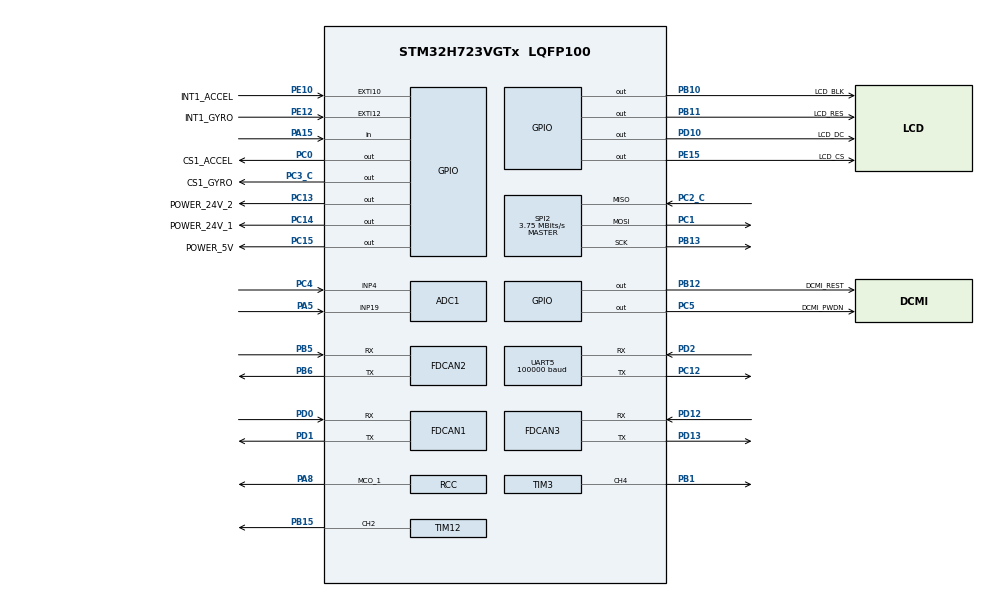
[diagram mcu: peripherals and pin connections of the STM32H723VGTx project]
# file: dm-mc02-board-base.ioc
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ADC1.Channel-0\#ChannelRegularConversion=ADC_CHANNEL_4
ADC1.Channel-1\#ChannelRegularConversion=ADC_CHANNEL_19
ADC1.ClockPrescaler=ADC_CLOCK_ASYNC_DIV64
ADC1.ContinuousConvMode=ENABLE
ADC1.ConversionDataManagement=ADC_CONVERSIONDATA_DMA_CIRCULAR
ADC1.NbrOfConversion=2
ADC1.NbrOfConversionFlag=1
ADC1.OffsetNumber-0\#ChannelRegularConversion=ADC_OFFSET_NONE
ADC1.OffsetNumber-1\#ChannelRegularConversion=ADC_OFFSET_NONE
ADC1.OffsetSignedSaturation-0\#ChannelRegularConversion=DISABLE
ADC1.OffsetSignedSaturation-1\#ChannelRegularConversion=DISABLE
ADC1.Rank-0\#ChannelRegularConversion=1
ADC1.Rank-1\#ChannelRegularConversion=2
ADC1.SamplingTime-0\#ChannelRegularConversion=ADC_SAMPLETIME_32CYCLES_5
ADC1.SamplingTime-1\#ChannelRegularConversion=ADC_SAMPLETIME_32CYCLES_5
ADC1.master=1
CORTEX_M7.BaseAddress-Cortex_Memory_Protection_Unit_Region0_Settings=0x24000000
CORTEX_M7.CPU_DCache=Disabled
CORTEX_M7.CPU_ICache=Disabled
CORTEX_M7.Enable-Cortex_Memory_Protection_Unit_Region0_Settings=MPU_REGION_ENABLE
CORTEX_M7.IsBufferable-Cortex_Memory_Protection_Unit_Region0_Settings=MPU_ACCESS_BUFFERABLE
CORTEX_M7.IsCacheable-Cortex_Memory_Protection_Unit_Region0_Settings=MPU_ACCESS_CACHEABLE
CORTEX_M7.MPU_Control=__NULL
CORTEX_M7.Size-Cortex_Memory_Protection_Unit_Region0_Settings=MPU_REGION_SIZE_512B
CORTEX_M7.TypeExtField-Cortex_Memory_Protection_Unit_Region0_Settings=MPU_TEX_LEVEL1
Dma.ADC1.0.Direction=DMA_PERIPH_TO_MEMORY
Dma.ADC1.0.EventEnable=DISABLE
Dma.ADC1.0.FIFOMode=DMA_FIFOMODE_DISABLE
Dma.ADC1.0.Instance=DMA1_Stream0
Dma.ADC1.0.MemDataAlignment=DMA_MDATAALIGN_HALFWORD
Dma.ADC1.0.MemInc=DMA_MINC_ENABLE
Dma.ADC1.0.Mode=DMA_CIRCULAR
Dma.ADC1.0.PeriphDataAlignment=DMA_PDATAALIGN_HALFWORD
Dma.ADC1.0.PeriphInc=DMA_PINC_DISABLE
Dma.ADC1.0.Polarity=HAL_DMAMUX_REQ_GEN_RISING
Dma.ADC1.0.Priority=DMA_PRIORITY_LOW
Dma.ADC1.0.RequestNumber=1
Dma.ADC1.0.SignalID=NONE
Dma.ADC1.0.SyncEnable=DISABLE
Dma.ADC1.0.SyncPolarity=HAL_DMAMUX_SYNC_NO_EVENT
Dma.ADC1.0.SyncRequestNumber=1
Dma.ADC1.0.SyncSignalID=NONE
Dma.Request0=ADC1
Dma.Request1=UART5_RX
Dma.UART5_RX.1.Direction=DMA_PERIPH_TO_MEMORY
Dma.UART5_RX.1.EventEnable=DISABLE
Dma.UART5_RX.1.FIFOMode=DMA_FIFOMODE_DISABLE
Dma.UART5_RX.1.Instance=DMA1_Stream1
Dma.UART5_RX.1.MemDataAlignment=DMA_MDATAALIGN_BYTE
Dma.UART5_RX.1.MemInc=DMA_MINC_ENABLE
Dma.UART5_RX.1.Mode=DMA_NORMAL
Dma.UART5_RX.1.PeriphDataAlignment=DMA_PDATAALIGN_BYTE
Dma.UART5_RX.1.PeriphInc=DMA_PINC_DISABLE
Dma.UART5_RX.1.Polarity=HAL_DMAMUX_REQ_GEN_RISING
Dma.UART5_RX.1.Priority=DMA_PRIORITY_VERY_HIGH
Dma.UART5_RX.1.RequestNumber=1
Dma.UART5_RX.1.SignalID=NONE
Dma.UART5_RX.1.SyncEnable=DISABLE
Dma.UART5_RX.1.SyncPolarity=HAL_DMAMUX_SYNC_NO_EVENT
Dma.UART5_RX.1.SyncRequestNumber=1
Dma.UART5_RX.1.SyncSignalID=NONE
FDCAN1.CalculateBaudRateNominal=1000000
FDCAN1.CalculateTimeBitNominal=1000
FDCAN1.CalculateTimeQuantumNominal=200.0
FDCAN1.NominalPrescaler=24
FDCAN1.NominalTimeSeg1=2
FDCAN1.RxFifo0ElmtsNbr=32
FDCAN1.StdFiltersNbr=1
FDCAN1.TxFifoQueueElmtsNbr=32
FDCAN2.CalculateBaudRateNominal=1000000
FDCAN2.CalculateTimeBitNominal=1000
FDCAN2.CalculateTimeQuantumNominal=200.0
FDCAN2.MessageRAMOffset=0x406
FDCAN2.NominalPrescaler=24
FDCAN2.RxFifo0ElmtsNbr=32
FDCAN2.StdFiltersNbr=1
FDCAN2.TxFifoQueueElmtsNbr=32
FDCAN3.CalculateBaudRateNominal=1000000
FDCAN3.CalculateTimeBitNominal=1000
FDCAN3.CalculateTimeQuantumNominal=200.0
FDCAN3.MessageRAMOffset=0x812
FDCAN3.NominalPrescaler=24
FDCAN3.RxFifo0ElmtsNbr=32
FDCAN3.StdFiltersNbr=1
FDCAN3.TxFifoQueueElmtsNbr=32
FREERTOS.INCLUDE_eTaskGetState=1
FREERTOS.INCLUDE_uxTaskGetStackHighWaterMark=1
FREERTOS.INCLUDE_vTaskDelayUntil=1
FREERTOS.INCLUDE_xQueueGetMutexHolder=1
FREERTOS.INCLUDE_xTaskGetCurrentTaskHandle=1
FREERTOS.INCLUDE_xTimerPendFunctionCall=1
FREERTOS.Tasks01=defaultTask,0,128,StartDefaultTask,Default,NULL,Dynamic,NULL,NULL
FREERTOS.configENABLE_FPU=1
FREERTOS.configGENERATE_RUN_TIME_STATS=1
FREERTOS.configRECORD_STACK_HIGH_ADDRESS=1
FREERTOS.configUSE_COUNTING_SEMAPHORES=1
FREERTOS.configUSE_RECURSIVE_MUTEXES=1
FREERTOS.configUSE_TIMERS=1
FREERTOS.configUSE_TRACE_FACILITY=1
Mcu.Family=STM32H7
Mcu.Name=STM32H723VGTx
Mcu.Package=LQFP100
NVIC.DMA1_Stream0_IRQn=true\:5\:0\:false\:false\:true\:false\:false\:true\:true
NVIC.DMA1_Stream1_IRQn=true\:5\:0\:false\:false\:true\:true\:false\:true\:true
NVIC.FDCAN1_IT0_IRQn=true\:5\:0\:false\:false\:true\:true\:true\:true\:true
NVIC.FDCAN1_IT1_IRQn=true\:5\:0\:false\:false\:true\:true\:true\:true\:true
NVIC.FDCAN2_IT0_IRQn=true\:5\:0\:false\:false\:true\:true\:true\:true\:true
NVIC.FDCAN2_IT1_IRQn=true\:5\:0\:false\:false\:true\:true\:true\:true\:true
NVIC.FDCAN3_IT0_IRQn=true\:5\:0\:false\:false\:true\:true\:true\:true\:true
NVIC.FDCAN3_IT1_IRQn=true\:5\:0\:false\:false\:true\:true\:true\:true\:true
NVIC.PriorityGroup=NVIC_PRIORITYGROUP_4
NVIC.TIM23_IRQn=true\:15\:0\:false\:false\:true\:false\:false\:true\:true
NVIC.TimeBase=TIM23_IRQn
NVIC.TimeBaseIP=TIM23
NVIC.UART5_IRQn=true\:5\:0\:false\:false\:true\:true\:true\:true\:true
PA0.Signal=S_TIM2_CH1_ETR
PA1.Signal=OCTOSPIM_P1_IO3
PA10.Signal=USART1_RX
PA13(JTMS/SWDIO).Mode=Serial_Wire
PA13(JTMS/SWDIO).Signal=DEBUG_JTMS-SWDIO
PA14(JTCK/SWCLK).Mode=Serial_Wire
PA14(JTCK/SWCLK).Signal=DEBUG_JTCK-SWCLK
PA15(JTDI).Signal=GPIO_Input
PA2.Signal=S_TIM2_CH3
PA3.Signal=OCTOSPIM_P1_IO2
PA5.Signal=ADCx_INP19
PA8.Mode=Clock-out-1
PA8.Signal=RCC_MCO_1
PA9.Signal=USART1_TX
PB0.Signal=OCTOSPIM_P1_IO1
PB1.Signal=S_TIM3_CH4
PB10.GPIO_Label=LCD_BLK
PB10.Signal=GPIO_Output
PB11.GPIO_Label=LCD_RES
PB11.Signal=GPIO_Output
PB12.GPIO_Label=DCMI_REST
PB12.GPIO_PuPd=GPIO_PULLUP
PB12.GPIO_Speed=GPIO_SPEED_FREQ_VERY_HIGH
PB12.PinState=GPIO_PIN_SET
PB12.Signal=GPIO_Output
PB13.GPIO_Speed=GPIO_SPEED_FREQ_VERY_HIGH
PB13.Mode=Full_Duplex_Master
PB13.Signal=SPI2_SCK
PB15.Signal=S_TIM12_CH2
PB2.Signal=OCTOSPIM_P1_CLK
PB5.Mode=FDCAN_Activate
PB5.Signal=FDCAN2_RX
PB6.Mode=FDCAN_Activate
PB6.Signal=FDCAN2_TX
PC0.GPIO_Label=CS1_ACCEL
PC0.GPIO_Speed=GPIO_SPEED_FREQ_VERY_HIGH
PC0.PinState=GPIO_PIN_SET
PC0.Signal=GPIO_Output
PC1.GPIO_Speed=GPIO_SPEED_FREQ_VERY_HIGH
PC1.Mode=Full_Duplex_Master
PC1.Signal=SPI2_MOSI
PC12.Mode=Asynchronous
PC12.Signal=UART5_TX
PC13.GPIO_Label=POWER_24V_2
PC13.PinState=GPIO_PIN_SET
PC13.Signal=GPIO_Output
PC14-OSC32_IN.GPIO_Label=POWER_24V_1
PC14-OSC32_IN.PinState=GPIO_PIN_SET
PC14-OSC32_IN.Signal=GPIO_Output
PC15-OSC32_OUT.GPIO_Label=POWER_5V
PC15-OSC32_OUT.PinState=GPIO_PIN_SET
PC15-OSC32_OUT.Signal=GPIO_Output
PC2_C.GPIO_Speed=GPIO_SPEED_FREQ_VERY_HIGH
PC2_C.Mode=Full_Duplex_Master
PC2_C.Signal=SPI2_MISO
PC3_C.GPIO_Label=CS1_GYRO
PC3_C.GPIO_Speed=GPIO_SPEED_FREQ_VERY_HIGH
PC3_C.PinState=GPIO_PIN_SET
PC3_C.Signal=GPIO_Output
PC4.Signal=ADCx_INP4
PC5.GPIO_Label=DCMI_PWDN
PC5.GPIO_PuPd=GPIO_NOPULL
PC5.GPIO_Speed=GPIO_SPEED_FREQ_VERY_HIGH
PC5.PinState=GPIO_PIN_SET
PC5.Signal=GPIO_Output
PD0.Mode=FDCAN_Activate
PD0.Signal=FDCAN1_RX
PD1.Mode=FDCAN_Activate
PD1.Signal=FDCAN1_TX
PD10.GPIO_Label=LCD_DC
PD10.Signal=GPIO_Output
PD11.Signal=OCTOSPIM_P1_IO0
PD12.Mode=FDCAN_Activate
PD12.Signal=FDCAN3_RX
PD13.Mode=FDCAN_Activate
PD13.Signal=FDCAN3_TX
PD2.GPIO_Speed=GPIO_SPEED_FREQ_VERY_HIGH
PD2.Mode=Asynchronous
PD2.Signal=UART5_RX
PD4.Signal=USART2_DE
PD5.Signal=USART2_TX
PD6.Signal=USART2_RX
PD7.GPIO_Speed=GPIO_SPEED_FREQ_VERY_HIGH
PD7.Signal=SPI1_MOSI
PE10.GPIO_Label=INT1_ACCEL
PE10.Signal=GPXTI10
PE11.Signal=OCTOSPIM_P1_NCS
PE12.GPIO_Label=INT1_GYRO
PE12.Signal=GPXTI12
PE15.GPIO_Label=LCD_CS
PE15.Signal=GPIO_Output
PE9.Signal=S_TIM1_CH1
PH0-OSC_IN.Mode=HSE-External-Oscillator
PH0-OSC_IN.Signal=RCC_OSC_IN
PH1-OSC_OUT.Mode=HSE-External-Oscillator
PH1-OSC_OUT.Signal=RCC_OSC_OUT
ProjectManager.HeapSize=0x200
ProjectManager.StackSize=0x800
ProjectManager.TargetToolchain=Makefile
RCC.ADCFreq_Value=96000000
RCC.APB1Freq_Value=120000000
RCC.APB2Freq_Value=120000000
RCC.APB3Freq_Value=120000000
RCC.APB4Freq_Value=120000000
RCC.CortexFreq_Value=480000000
RCC.D1PPRE=RCC_APB3_DIV2
RCC.D2PPRE1=RCC_APB1_DIV2
RCC.D2PPRE2=RCC_APB2_DIV2
RCC.D3PPRE=RCC_APB4_DIV2
RCC.DIVM1=2
RCC.DIVM2=2
RCC.DIVN1=40
RCC.DIVN2=16
RCC.DIVP1=1
RCC.DIVQ1=4
RCC.EnbaleCSS=false
RCC.HCLKFreq_Value=240000000
RCC.HPRE=RCC_HCLK_DIV2
RCC.HSE_VALUE=24000000
RCC.PLL2FRACN=0
RCC.PLL2_VCI_Range-AdvancedSettings=RCC_PLL2VCIRANGE_0
RCC.PLL2_VCO_SEL-AdvancedSettings=RCC_PLL2VCOWIDE
RCC.PLL3FRACN=0
RCC.PLL3_VCO_SEL-AdvancedSettings=RCC_PLL3VCOMEDIUM
RCC.PLLFRACN=0
RCC.PLLSourceVirtual=RCC_PLLSOURCE_HSE
RCC.SPI6CLockSelection=RCC_SPI6CLKSOURCE_HSE
RCC.SYSCLKFreq_VALUE=480000000
RCC.SYSCLKSource=RCC_SYSCLKSOURCE_PLLCLK
RCC.USBCLockSelection=RCC_USBCLKSOURCE_HSI48
RCC.USBFreq_Value=48000000
SH.ADCx_INP19.0=ADC1_INP19,IN19-Single-Ended
SH.ADCx_INP4.0=ADC1_INP4,IN4-Single-Ended
SH.S_TIM12_CH2.0=TIM12_CH2,PWM Generation2 CH2
SH.S_TIM1_CH1.0=TIM1_CH1
SH.S_TIM2_CH1_ETR.0=TIM2_CH1
SH.S_TIM2_CH3.0=TIM2_CH3
SH.S_TIM3_CH4.0=TIM3_CH4,PWM Generation4 CH4
SPI2.BaudRatePrescaler=SPI_BAUDRATEPRESCALER_32
SPI2.CLKPhase=SPI_PHASE_2EDGE
SPI2.CLKPolarity=SPI_POLARITY_HIGH
SPI2.CalculateBaudRate=3.75 MBits/s
SPI2.DataSize=SPI_DATASIZE_8BIT
SPI2.Direction=SPI_DIRECTION_2LINES
SPI2.Mode=SPI_MODE_MASTER
SPI2.VirtualType=VM_MASTER
TIM12.Channel-PWM\ Generation2\ CH2=TIM_CHANNEL_2
TIM12.Period=65535
TIM12.Prescaler=24-1
TIM3.AutoReloadPreload=TIM_AUTORELOAD_PRELOAD_ENABLE
TIM3.Channel-PWM\ Generation4\ CH4=TIM_CHANNEL_4
TIM3.Period=10000-1
TIM3.Prescaler=24-1
TIM6.Prescaler=12000-1
UART5.BaudRate=100000
UART5.Parity=PARITY_EVEN
UART5.StopBits=UART_STOPBITS_2
UART5.WordLength=WORDLENGTH_9B
VP_FREERTOS_VS_CMSIS_V1.Mode=CMSIS_V1
VP_MEMORYMAP_VS_MEMORYMAP.Mode=CurAppReg
VP_SYS_VS_tim23.Mode=TIM23
VP_TIM6_VS_ClockSourceINT.Mode=Enable_Timer
board=custom

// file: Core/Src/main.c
/* USER CODE BEGIN Header */
/**
  ******************************************************************************
  * @file           : main.c
  * @brief          : Main program body
  ******************************************************************************
  * @attention
  *
  * Copyright (c) 2024 STMicroelectronics.
  * All rights reserved.
  *
  * This software is licensed under terms that can be found in the LICENSE file
  * in the root directory of this software component.
  * If no LICENSE file comes with this software, it is provided AS-IS.
  *
  ******************************************************************************
  */
/* USER CODE END Header */
#include "main.h"
#include "cmsis_os.h"
#include "adc.h"
#include "dma.h"
#include "fdcan.h"
#include "memorymap.h"
#include "spi.h"
#include "tim.h"
#include "usart.h"
#include "gpio.h"

/* USER CODE BEGIN Includes */
#include "robot.h"
/* USER CODE END Includes */

void SystemClock_Config(void);
void MX_FREERTOS_Init(void);

int main(void)
{

  /* MCU Configuration--------------------------------------------------------*/

  /* Reset of all peripherals, Initializes the Flash interface and the Systick. */
  HAL_Init();

  /* Configure the system clock */
  SystemClock_Config();

  /* Initialize all configured peripherals */
  MX_GPIO_Init();
  MX_DMA_Init();
  MX_ADC1_Init();
  MX_TIM12_Init();
  MX_SPI2_Init();
  MX_TIM3_Init();
  MX_FDCAN1_Init();
  MX_FDCAN2_Init();
  MX_FDCAN3_Init();
  MX_TIM6_Init();
  MX_UART5_Init();
  /* USER CODE BEGIN 2 */
  Robot_Init();
  /* USER CODE END 2 */

  /* Call init function for freertos objects (in cmsis_os2.c) */
  MX_FREERTOS_Init();

  /* Start scheduler */
  osKernelStart();

  /* We should never get here as control is now taken by the scheduler */

  /* Infinite loop */
  while (1)
  {

  }
}

void SystemClock_Config(void)
{
  RCC_OscInitTypeDef RCC_OscInitStruct = {0};
  RCC_ClkInitTypeDef RCC_ClkInitStruct = {0};

  /** Supply configuration update enable
  */
  HAL_PWREx_ConfigSupply(PWR_LDO_SUPPLY);

  /** Configure the main internal regulator output voltage
  */
  __HAL_PWR_VOLTAGESCALING_CONFIG(PWR_REGULATOR_VOLTAGE_SCALE0);

  while(!__HAL_PWR_GET_FLAG(PWR_FLAG_VOSRDY)) {}

  /** Initializes the RCC Oscillators according to the specified parameters
  * in the RCC_OscInitTypeDef structure.
  */
  RCC_OscInitStruct.OscillatorType = RCC_OSCILLATORTYPE_HSI|RCC_OSCILLATORTYPE_HSE;
  RCC_OscInitStruct.HSEState = RCC_HSE_ON;
  RCC_OscInitStruct.HSIState = RCC_HSI_DIV1;
  RCC_OscInitStruct.HSICalibrationValue = 64;
  RCC_OscInitStruct.PLL.PLLState = RCC_PLL_ON;
  RCC_OscInitStruct.PLL.PLLSource = RCC_PLLSOURCE_HSE;
  RCC_OscInitStruct.PLL.PLLM = 2;
  RCC_OscInitStruct.PLL.PLLN = 40;
  RCC_OscInitStruct.PLL.PLLP = 1;
  RCC_OscInitStruct.PLL.PLLQ = 4;
  RCC_OscInitStruct.PLL.PLLR = 2;
  RCC_OscInitStruct.PLL.PLLRGE = RCC_PLL1VCIRANGE_3;
  RCC_OscInitStruct.PLL.PLLVCOSEL = RCC_PLL1VCOWIDE;
  RCC_OscInitStruct.PLL.PLLFRACN = 0;
  if (HAL_RCC_OscConfig(&RCC_OscInitStruct) != HAL_OK)
  {
    Error_Handler();
  }

  /** Initializes the CPU, AHB and APB buses clocks
  */
  RCC_ClkInitStruct.ClockType = RCC_CLOCKTYPE_HCLK|RCC_CLOCKTYPE_SYSCLK
                              |RCC_CLOCKTYPE_PCLK1|RCC_CLOCKTYPE_PCLK2
                              |RCC_CLOCKTYPE_D3PCLK1|RCC_CLOCKTYPE_D1PCLK1;
  RCC_ClkInitStruct.SYSCLKSource = RCC_SYSCLKSOURCE_PLLCLK;
  RCC_ClkInitStruct.SYSCLKDivider = RCC_SYSCLK_DIV1;
  RCC_ClkInitStruct.AHBCLKDivider = RCC_HCLK_DIV2;
  RCC_ClkInitStruct.APB3CLKDivider = RCC_APB3_DIV2;
  RCC_ClkInitStruct.APB1CLKDivider = RCC_APB1_DIV2;
  RCC_ClkInitStruct.APB2CLKDivider = RCC_APB2_DIV2;
  RCC_ClkInitStruct.APB4CLKDivider = RCC_APB4_DIV2;

  if (HAL_RCC_ClockConfig(&RCC_ClkInitStruct, FLASH_LATENCY_3) != HAL_OK)
  {
    Error_Handler();
  }
  HAL_RCC_MCOConfig(RCC_MCO1, RCC_MCO1SOURCE_HSI, RCC_MCODIV_1);
}

void HAL_TIM_PeriodElapsedCallback(TIM_HandleTypeDef *htim)
{
  if (htim->Instance == TIM23) {
    HAL_IncTick();
  }
}

void Error_Handler(void)
{
  __disable_irq();
  while (1)
  {
  }
}

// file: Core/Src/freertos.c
/* USER CODE BEGIN Header */
/**
  ******************************************************************************
  * File Name          : freertos.c
  * Description        : Code for freertos applications
  ******************************************************************************
  * @attention
  *
  * Copyright (c) 2024 STMicroelectronics.
  * All rights reserved.
  *
  * This software is licensed under terms that can be found in the LICENSE file
  * in the root directory of this software component.
  * If no LICENSE file comes with this software, it is provided AS-IS.
  *
  ******************************************************************************
  */
/* USER CODE END Header */

#include "FreeRTOS.h"
#include "task.h"
#include "main.h"
#include "cmsis_os.h"

/* USER CODE BEGIN Includes */
#include "tim.h"
/* USER CODE END Includes */

osThreadId defaultTaskHandle;

void StartDefaultTask(void const * argument);

void MX_FREERTOS_Init(void); /* (MISRA C 2004 rule 8.1) */

/* GetIdleTaskMemory prototype (linked to static allocation support) */
void vApplicationGetIdleTaskMemory( StaticTask_t **ppxIdleTaskTCBBuffer, StackType_t **ppxIdleTaskStackBuffer, uint32_t *pulIdleTaskStackSize );

/* GetTimerTaskMemory prototype (linked to static allocation support) */
void vApplicationGetTimerTaskMemory( StaticTask_t **ppxTimerTaskTCBBuffer, StackType_t **ppxTimerTaskStackBuffer, uint32_t *pulTimerTaskStackSize );

/* Hook prototypes */
void configureTimerForRunTimeStats(void);
unsigned long getRunTimeCounterValue(void);

/* USER CODE BEGIN 1 */
/* Functions needed when configGENERATE_RUN_TIME_STATS is on */
__weak void configureTimerForRunTimeStats(void)
{
  HAL_TIM_Base_Start(&htim6);
}

__weak unsigned long getRunTimeCounterValue(void)
{
  return __HAL_TIM_GET_COUNTER(&htim6);
}
/* USER CODE END 1 */

/* USER CODE BEGIN GET_IDLE_TASK_MEMORY */
static StaticTask_t xIdleTaskTCBBuffer;
static StackType_t xIdleStack[configMINIMAL_STACK_SIZE];

void vApplicationGetIdleTaskMemory( StaticTask_t **ppxIdleTaskTCBBuffer, StackType_t **ppxIdleTaskStackBuffer, uint32_t *pulIdleTaskStackSize )
{
  *ppxIdleTaskTCBBuffer = &xIdleTaskTCBBuffer;
  *ppxIdleTaskStackBuffer = &xIdleStack[0];
  *pulIdleTaskStackSize = configMINIMAL_STACK_SIZE;
  /* place for user code */
}
/* USER CODE END GET_IDLE_TASK_MEMORY */

/* USER CODE BEGIN GET_TIMER_TASK_MEMORY */
static StaticTask_t xTimerTaskTCBBuffer;
static StackType_t xTimerStack[configTIMER_TASK_STACK_DEPTH];

void vApplicationGetTimerTaskMemory( StaticTask_t **ppxTimerTaskTCBBuffer, StackType_t **ppxTimerTaskStackBuffer, uint32_t *pulTimerTaskStackSize )
{
  *ppxTimerTaskTCBBuffer = &xTimerTaskTCBBuffer;
  *ppxTimerTaskStackBuffer = &xTimerStack[0];
  *pulTimerTaskStackSize = configTIMER_TASK_STACK_DEPTH;
  /* place for user code */
}
/* USER CODE END GET_TIMER_TASK_MEMORY */

void MX_FREERTOS_Init(void) {

  /* Create the thread(s) */
  /* definition and creation of defaultTask */
  osThreadDef(defaultTask, StartDefaultTask, osPriorityNormal, 0, 128);
  defaultTaskHandle = osThreadCreate(osThread(defaultTask), NULL);

}

void StartDefaultTask(void const * argument)
{
  for(;;)
  {
    osDelay(1);
  }
}
